AUTOSAR XML (schema 00046)
package /ComponentTypes
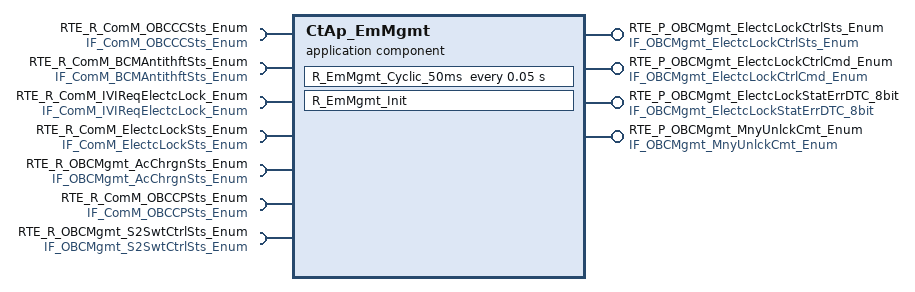
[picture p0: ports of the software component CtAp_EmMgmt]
  application sw component type CtAp_EmMgmt
    4 x provide port:
      RTE_P_OBCMgmt_ElectcLockCtrlSts_Enum: nonqueued-sender-com-spec{data-element=tec_OBCMgmt_ElectcLockCtrlSts_Enum, init-value=0}, provided-interface=IF_OBCMgmt_ElectcLockCtrlSts_Enum
      RTE_P_OBCMgmt_ElectcLockCtrlCmd_Enum: nonqueued-sender-com-spec{data-element=tec_OBCMgmt_ElectcLockCtrlCmd_Enum, init-value=0}, provided-interface=IF_OBCMgmt_ElectcLockCtrlCmd_Enum
      RTE_P_OBCMgmt_ElectcLockStatErrDTC_8bit: nonqueued-sender-com-spec{data-element=tec_OBCMgmt_ElectcLockStatErrDTC_8bit, init-value=0}, provided-interface=IF_OBCMgmt_ElectcLockStatErrDTC_8bit
      RTE_P_OBCMgmt_MnyUnlckCmt_Enum: nonqueued-sender-com-spec{data-element=tec_OBCMgmt_MnyUnlckCmt_Enum, init-value=0}, provided-interface=IF_OBCMgmt_MnyUnlckCmt_Enum
    7 x require port:
      RTE_R_ComM_OBCCCSts_Enum: nonqueued-receiver-com-spec{data-element=tec_ComM_OBCCCSts_Enum, filter=data-filter-type=ALWAYS, init-value=0}, required-interface=IF_ComM_OBCCCSts_Enum
      RTE_R_ComM_BCMAntithftSts_Enum: nonqueued-receiver-com-spec{data-element=tec_ComM_BCMAntithftSts_Enum, filter=data-filter-type=ALWAYS, init-value=0}, required-interface=IF_ComM_BCMAntithftSts_Enum
      RTE_R_ComM_IVIReqElectcLock_Enum: nonqueued-receiver-com-spec{data-element=tec_ComM_IVIReqElectcLock_Enum, filter=data-filter-type=ALWAYS, init-value=0}, required-interface=IF_ComM_IVIReqElectcLock_Enum
      RTE_R_ComM_ElectcLockSts_Enum: nonqueued-receiver-com-spec{data-element=tec_ComM_ElectcLockSts_Enum, filter=data-filter-type=ALWAYS, init-value=0}, required-interface=IF_ComM_ElectcLockSts_Enum
      RTE_R_OBCMgmt_AcChrgnSts_Enum: nonqueued-receiver-com-spec{data-element=tec_OBCMgmt_AcChrgnSts_Enum, filter=data-filter-type=ALWAYS, init-value=0}, required-interface=IF_OBCMgmt_AcChrgnSts_Enum
      RTE_R_ComM_OBCCPSts_Enum: nonqueued-receiver-com-spec{data-element=tec_ComM_OBCCPSts_Enum, filter=data-filter-type=ALWAYS, init-value=0}, required-interface=IF_ComM_OBCCPSts_Enum
      RTE_R_OBCMgmt_S2SwtCtrlSts_Enum: nonqueued-receiver-com-spec{data-element=tec_OBCMgmt_S2SwtCtrlSts_Enum, filter=data-filter-type=ALWAYS, init-value=0}, required-interface=IF_OBCMgmt_S2SwtCtrlSts_Enum
    behavior CtAp_EmMgmt_InternalBehavior
      init event CtAp_EmMgmt_InitEvent: start-on-event=R_EmMgmt_Init
      timing event TMT_R_EmMgmt_Cyclic_50ms: start-on-event=R_EmMgmt_Cyclic_50ms, period=0.05
      runnable R_EmMgmt_Init
      runnable R_EmMgmt_Cyclic_50ms
        data-receive-point-by-arguments:
          7 x access:
            REC_RTE_R_ComM_BCMAntithftSts_Enum_tec_ComM_BCMAntithftSts_Enum: accessed-variable=RTE_R_ComM_BCMAntithftSts_Enum.tec_ComM_BCMAntithftSts_Enum
            REC_RTE_R_ComM_ElectcLockSts_Enum_tec_ComM_ElectcLockSts_Enum: accessed-variable=RTE_R_ComM_ElectcLockSts_Enum.tec_ComM_ElectcLockSts_Enum
            REC_RTE_R_ComM_IVIReqElectcLock_Enum_tec_ComM_IVIReqElectcLock_Enum: accessed-variable=RTE_R_ComM_IVIReqElectcLock_Enum.tec_ComM_IVIReqElectcLock_Enum
            REC_RTE_R_ComM_OBCCCSts_Enum_tec_ComM_OBCCCSts_Enum: accessed-variable=RTE_R_ComM_OBCCCSts_Enum.tec_ComM_OBCCCSts_Enum
            REC_RTE_R_ComM_OBCCPSts_Enum_tec_ComM_OBCCPSts_Enum: accessed-variable=RTE_R_ComM_OBCCPSts_Enum.tec_ComM_OBCCPSts_Enum
            REC_RTE_R_OBCMgmt_AcChrgnSts_Enum_tec_OBCMgmt_AcChrgnSts_Enum: accessed-variable=RTE_R_OBCMgmt_AcChrgnSts_Enum.tec_OBCMgmt_AcChrgnSts_Enum
            REC_RTE_R_OBCMgmt_S2SwtCtrlSts_Enum_tec_OBCMgmt_S2SwtCtrlSts_Enum: accessed-variable=RTE_R_OBCMgmt_S2SwtCtrlSts_Enum.tec_OBCMgmt_S2SwtCtrlSts_Enum
        data-send-points:
          4 x access:
            SEND_RTE_P_OBCMgmt_ElectcLockCtrlCmd_Enum_tec_OBCMgmt_ElectcLockCtrlCmd_Enum: accessed-variable=RTE_P_OBCMgmt_ElectcLockCtrlCmd_Enum.tec_OBCMgmt_ElectcLockCtrlCmd_Enum
            SEND_RTE_P_OBCMgmt_ElectcLockCtrlSts_Enum_tec_OBCMgmt_ElectcLockCtrlSts_Enum: accessed-variable=RTE_P_OBCMgmt_ElectcLockCtrlSts_Enum.tec_OBCMgmt_ElectcLockCtrlSts_Enum
            SEND_RTE_P_OBCMgmt_ElectcLockStatErrDTC_8bit_tec_OBCMgmt_ElectcLockStatErrDTC_8bit: accessed-variable=RTE_P_OBCMgmt_ElectcLockStatErrDTC_8bit.tec_OBCMgmt_ElectcLockStatErrDTC_8bit
            SEND_RTE_P_OBCMgmt_MnyUnlckCmt_Enum_tec_OBCMgmt_MnyUnlckCmt_Enum: accessed-variable=RTE_P_OBCMgmt_MnyUnlckCmt_Enum.tec_OBCMgmt_MnyUnlckCmt_Enum
  swc implementation CtAp_EmMgmt_Implementation: behavior=CtAp_EmMgmt_InternalBehavior
    code-descriptors:
      code Default: artifact-descriptors=autosar-engineering-object=category=SWOBJ
